# PIC32MZ1024EFM144 register map
Vendor: Microchip
Registers are 32-bit, read-write, reset 0x0 unless marked. A register's access mark holds for its fields unless they carry their own. Addresses are absolute, and some are shared; only a register's first bit layout is shown; [hi:lo] are bit positions; {n}, {i} and the like mark numbered series.

## CAN2
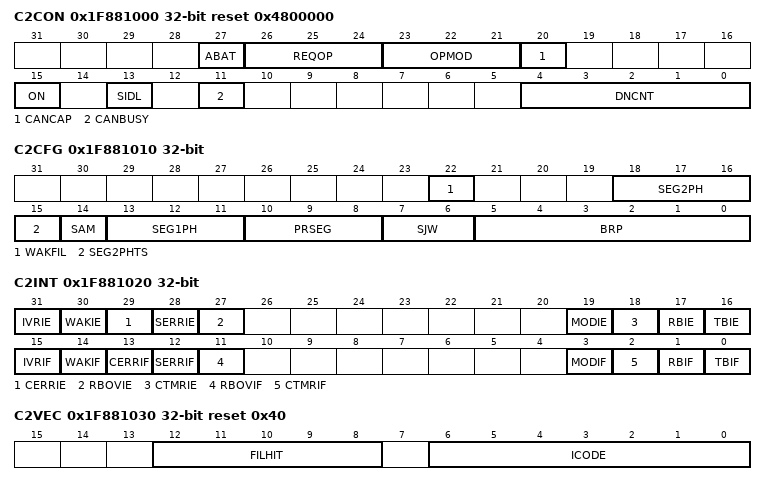
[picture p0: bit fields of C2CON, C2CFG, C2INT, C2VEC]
0x1F881000 C2CON reset 0x4800000
  [27] ABAT — (can only be set)
  [26:24] REQOP
  [23:21] OPMOD ro
  [20] CANCAP
  [15] ON
  [13] SIDL
  [11] CANBUSY ro
  [4:0] DNCNT
0x1F881010 C2CFG
  [22] WAKFIL, [18:16] SEG2PH, [15] SEG2PHTS, [14] SAM, [13:11] SEG1PH, [10:8] PRSEG, [7:6] SJW, [5:0] BRP
0x1F881020 C2INT
  [31] IVRIE, [30] WAKIE, [29] CERRIE, [28] SERRIE, [27] RBOVIE, [19] MODIE, [18] CTMRIE, [17] RBIE, [16] TBIE, [15] IVRIF, [14] WAKIF, [13] CERRIF, [12] SERRIF, [11] RBOVIF, [3] MODIF, [2] CTMRIF, [1] RBIF, [0] TBIF
0x1F881030 C2VEC ro reset 0x40
  [12:8] FILHIT, [6:0] ICODE
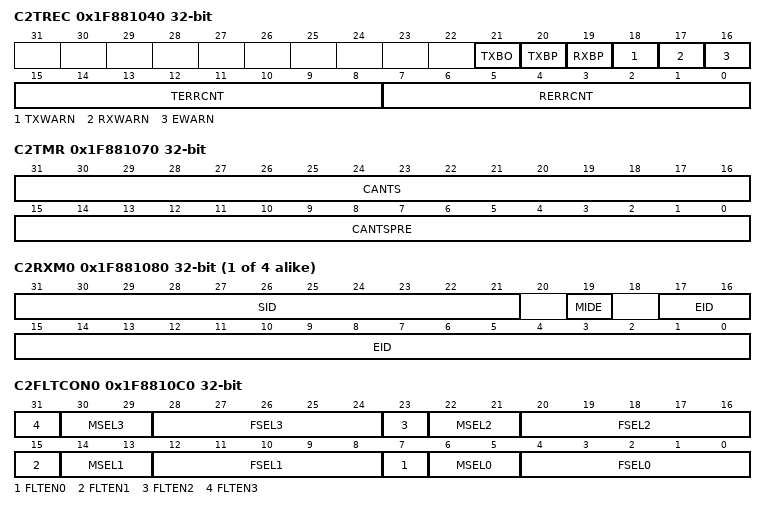
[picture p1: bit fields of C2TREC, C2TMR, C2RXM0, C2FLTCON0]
0x1F881040 C2TREC ro
  [21] TXBO, [20] TXBP, [19] RXBP, [18] TXWARN, [17] RXWARN, [16] EWARN, [15:8] TERRCNT, [7:0] RERRCNT
0x1F881050 C2FSTAT ro
  [31:0] FIFOIP
0x1F881060 C2RXOVF ro
  [31:0] RXOVF
0x1F881070 C2TMR
  [31:16] CANTS, [15:0] CANTSPRE
{0x1F881080+0x10*i} C2RXM{i} (i=0..3)
  [31:21] SID, [19] MIDE, [17:0] EID
0x1F8810C0 C2FLTCON0
  [8n+7] FLTEN{n} (n=0..3), [8n+6:8n+5] MSEL{n} (n=0..3), [8n+4:8n] FSEL{n} (n=0..3)
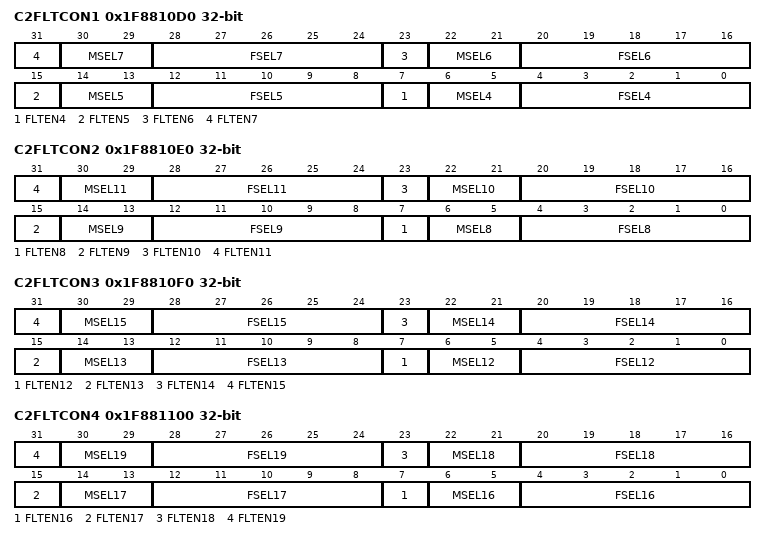
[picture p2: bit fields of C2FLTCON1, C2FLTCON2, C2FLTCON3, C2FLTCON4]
0x1F8810D0 C2FLTCON1
  [8n-25] FLTEN{n} (n=4..7), [8n-26:8n-27] MSEL{n} (n=4..7), [8n-28:8n-32] FSEL{n} (n=4..7)
0x1F8810E0 C2FLTCON2
  [8n-57] FLTEN{n} (n=8..11), [8n-58:8n-59] MSEL{n} (n=8..11), [8n-60:8n-64] FSEL{n} (n=8..11)
0x1F8810F0 C2FLTCON3
  [8n-89] FLTEN{n} (n=12..15), [8n-90:8n-91] MSEL{n} (n=12..15), [8n-92:8n-96] FSEL{n} (n=12..15)
0x1F881100 C2FLTCON4
  [8n-121] FLTEN{n} (n=16..19), [8n-122:8n-123] MSEL{n} (n=16..19), [8n-124:8n-128] FSEL{n} (n=16..19)
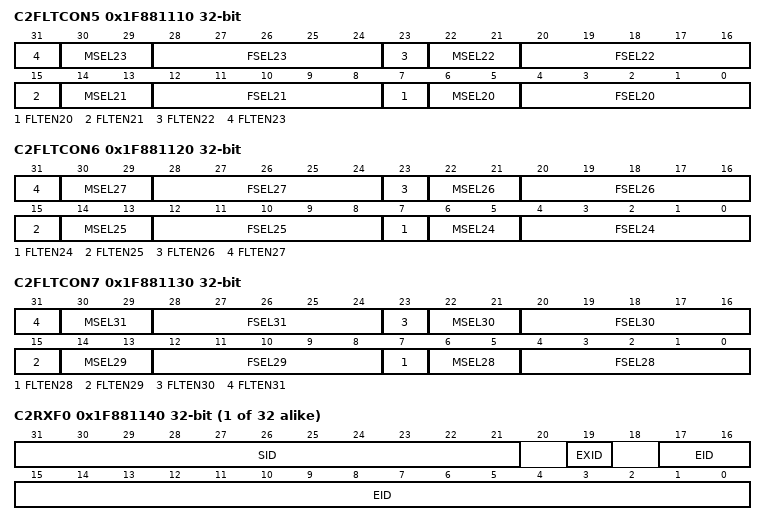
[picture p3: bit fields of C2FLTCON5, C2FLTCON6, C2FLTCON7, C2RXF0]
0x1F881110 C2FLTCON5
  [8n-153] FLTEN{n} (n=20..23), [8n-154:8n-155] MSEL{n} (n=20..23), [8n-156:8n-160] FSEL{n} (n=20..23)
0x1F881120 C2FLTCON6
  [8n-185] FLTEN{n} (n=24..27), [8n-186:8n-187] MSEL{n} (n=24..27), [8n-188:8n-192] FSEL{n} (n=24..27)
0x1F881130 C2FLTCON7
  [8n-217] FLTEN{n} (n=28..31), [8n-218:8n-219] MSEL{n} (n=28..31), [8n-220:8n-224] FSEL{n} (n=28..31)
{0x1F881140+0x10*i} C2RXF{i} reset not defined (i=0..31) — (power-on value xxxxxxxxxxx0x0xxxxxxxxxxxxxxxxxx)
  [31:21] SID, [19] EXID, [17:0] EID
0x1F881340 C2FIFOBA
  [31:2] FIFOBA
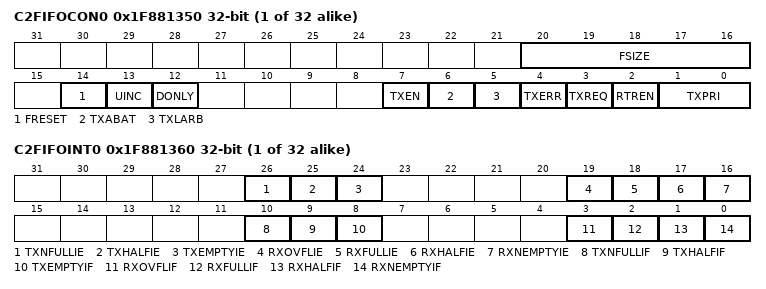
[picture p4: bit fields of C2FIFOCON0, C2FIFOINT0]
{0x1F881350+0x40*i} C2FIFOCON{i} (i=0..31)
  [20:16] FSIZE, [14] FRESET, [13] UINC, [12] DONLY, [7] TXEN, [6] TXABAT, [5] TXLARB, [4] TXERR, [3] TXREQ, [2] RTREN, [1:0] TXPRI
{0x1F881360+0x40*i} C2FIFOINT{i} (i=0..31)
  [26] TXNFULLIE, [25] TXHALFIE, [24] TXEMPTYIE, [19] RXOVFLIE, [18] RXFULLIE, [17] RXHALFIE, [16] RXNEMPTYIE, [10] TXNFULLIF ro, [9] TXHALFIF ro, [8] TXEMPTYIF ro, [3] RXOVFLIF, [2] RXFULLIF ro, [1] RXHALFIF ro, [0] RXNEMPTYIF ro
{0x1F881370+0x40*i} C2FIFOUA{i} ro reset not defined (i=0..31) — (power-on value xxxxxxxxxxxxxxxxxxxxxxxxxxxxxx00)
  [31:2] FIFOUA
{0x1F881380+0x40*i} C2FIFOCI{i} ro (i=0..31)
  [4:0] CFIFOCI

## usb_clk_rst
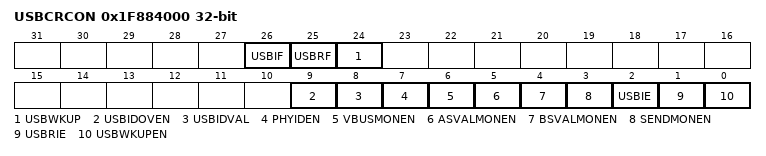
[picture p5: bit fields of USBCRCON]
0x1F884000 USBCRCON
  [26] USBIF ro, [25] USBRF, [24] USBWKUP, [9] USBIDOVEN, [8] USBIDVAL, [7] PHYIDEN, [6] VBUSMONEN, [5] ASVALMONEN, [4] BSVALMONEN, [3] SENDMONEN, [2] USBIE, [1] USBRIE, [0] USBWKUPEN

## PCACHE
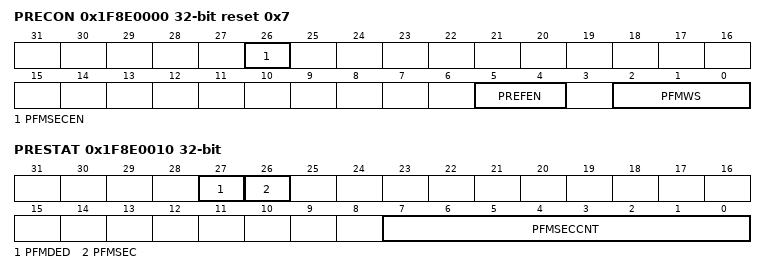
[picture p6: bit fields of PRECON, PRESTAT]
0x1F8E0000 PRECON reset 0x7
  [26] PFMSECEN, [5:4] PREFEN, [2:0] PFMWS
0x1F8E0010 PRESTAT
  [27] PFMDED, [26] PFMSEC, [7:0] PFMSECCNT

## EBI
{0x1F8E1014+4i} EBICS{i} (i=0..3)
  [31:16] CSADDR
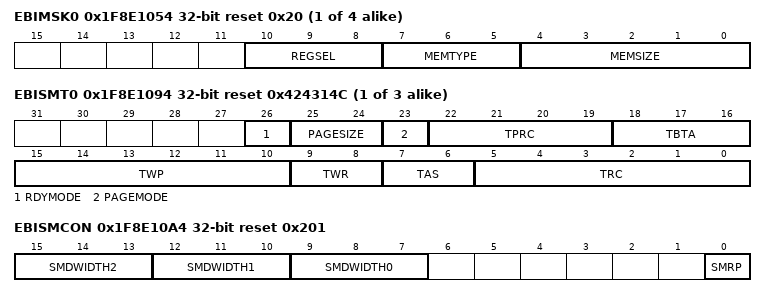
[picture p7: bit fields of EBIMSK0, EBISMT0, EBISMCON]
{0x1F8E1054+4i} EBIMSK{i} reset 0x20 (i=0..3)
  [10:8] REGSEL, [7:5] MEMTYPE, [4:0] MEMSIZE
{0x1F8E1094+4i} EBISMT{i} reset 0x424314C (i=0..2)
  [26] RDYMODE, [25:24] PAGESIZE, [23] PAGEMODE, [22:19] TPRC, [18:16] TBTA, [15:10] TWP, [9:8] TWR, [7:6] TAS, [5:0] TRC
0x1F8E10A0 EBIFTRPD reset 0x201
  [31:0] TRPD
0x1F8E10A4 EBISMCON reset 0x201
  [15:13] SMDWIDTH2, [12:10] SMDWIDTH1, [9:7] SMDWIDTH0, [0] SMRP

## DOS_EIP_00124_usb_hs_otgcore
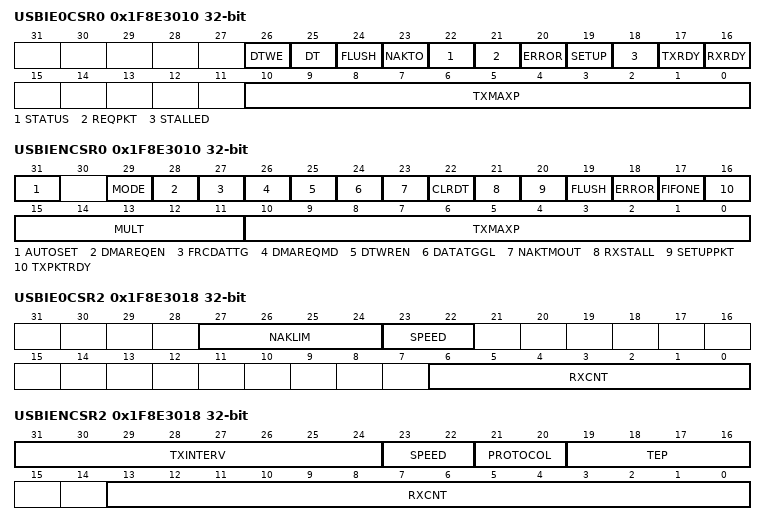
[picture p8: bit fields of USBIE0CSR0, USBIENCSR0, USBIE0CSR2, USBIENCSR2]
0x1F8E3010 USBIE0CSR0
  [26] DTWE, [25] DT, [24] FLUSH, [23] NAKTO, [22] STATUS, [21] REQPKT, [20] ERROR, [19] SETUP, [18] STALLED, [17] TXRDY, [16] RXRDY, [10:0] TXMAXP
0x1F8E3010 USBIENCSR0
  [31] AUTOSET, [29] MODE, [28] DMAREQEN, [27] FRCDATTG, [26] DMAREQMD, [25] DTWREN, [24] DATATGGL, [23] NAKTMOUT, [22] CLRDT, [21] RXSTALL, [20] SETUPPKT, [19] FLUSH, [18] ERROR, [17] FIFONE, [16] TXPKTRDY, [15:11] MULT, [10:0] TXMAXP
0x1F8E3018 USBIE0CSR2
  [27:24] NAKLIM, [23:22] SPEED, [6:0] RXCNT ro
0x1F8E3018 USBIENCSR2
  [31:24] TXINTERV, [23:22] SPEED, [21:20] PROTOCOL, [19:16] TEP, [13:0] RXCNT ro
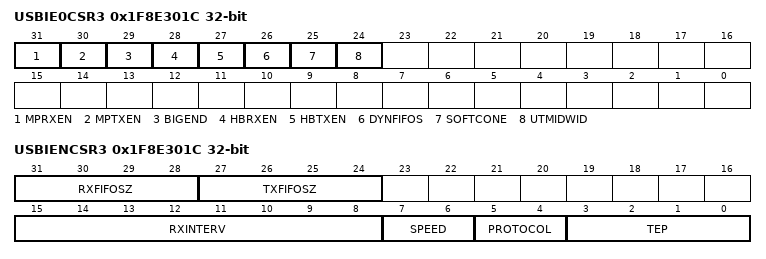
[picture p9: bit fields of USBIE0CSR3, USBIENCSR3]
0x1F8E301C USBIE0CSR3 ro reset not defined — (power-on value xx0xxx10------------------------)
  [31] MPRXEN, [30] MPTXEN, [29] BIGEND, [28] HBRXEN, [27] HBTXEN, [26] DYNFIFOS, [25] SOFTCONE, [24] UTMIDWID
0x1F8E301C USBIENCSR3 reset not defined — (power-on value xxxxxxxx--------0000000000000000)
  [31:28] RXFIFOSZ ro, [27:24] TXFIFOSZ ro, [15:8] RXINTERV, [7:6] SPEED, [5:4] PROTOCOL, [3:0] TEP
